AUTOSAR XML (schema 4-3-0)
package /E3_1_2_Premium
  system System
    system mapping Mapping_TestSwc_RGS_VL
      sw-mappings:
        swc to ecu mapping SwcMapping_TestSwc_RGS_VL: component=Geltungsbereich_E3_1_2_Premium.TestSwc, ecu-instance=RGS_VL
package /ComponentTypes
  composition sw component type Geltungsbereich_E3_1_2_Premium
    component TestSwc: type=TestSwc_RGS_VL
    delegate TestSwc.P_KN_RGS_VL_BusKnockOut <-> outer port P_KN_RGS_VL_BusKnockOut
    delegate TestSwc.P_KN_RGS_VL_BusKnockOutTimer <-> outer port P_KN_RGS_VL_BusKnockOutTimer
    delegate TestSwc.P_KN_RGS_VL_ECUKnockOut <-> outer port P_KN_RGS_VL_ECUKnockOut
    delegate TestSwc.P_KN_RGS_VL_ECUKnockOutTimer <-> outer port P_KN_RGS_VL_ECUKnockOutTimer
    delegate TestSwc.P_NM_RGS_VL_CBV_AWB <-> outer port P_NM_RGS_VL_CBV_AWB
    delegate TestSwc.P_NM_RGS_VL_CBV_CRI <-> outer port P_NM_RGS_VL_CBV_CRI
    delegate TestSwc.P_NM_RGS_VL_FCAB <-> outer port P_NM_RGS_VL_FCAB
    delegate TestSwc.P_NM_RGS_VL_FCIB <-> outer port P_NM_RGS_VL_FCIB
    delegate TestSwc.P_NM_RGS_VL_NM_State <-> outer port P_NM_RGS_VL_NM_State
    delegate TestSwc.P_NM_RGS_VL_NM_aktiv_Diag <-> outer port P_NM_RGS_VL_NM_aktiv_Diag
    delegate TestSwc.P_NM_RGS_VL_NM_aktiv_KL15 <-> outer port P_NM_RGS_VL_NM_aktiv_KL15
    delegate TestSwc.P_NM_RGS_VL_NM_aktiv_Mot_aktiv <-> outer port P_NM_RGS_VL_NM_aktiv_Mot_aktiv
    delegate TestSwc.P_NM_RGS_VL_NM_aktiv_Tmin <-> outer port P_NM_RGS_VL_NM_aktiv_Tmin
    delegate TestSwc.P_NM_RGS_VL_SNI_10 <-> outer port P_NM_RGS_VL_SNI_10
    delegate TestSwc.P_NM_RGS_VL_UDS_CC <-> outer port P_NM_RGS_VL_UDS_CC
    delegate TestSwc.P_NM_RGS_VL_Wakeup <-> outer port P_NM_RGS_VL_Wakeup
    delegate TestSwc.P_RGS_VL_Abschaltstufe <-> outer port P_RGS_VL_Abschaltstufe
    delegate TestSwc.P_RGS_VL_Bauteilfehler <-> outer port P_RGS_VL_Bauteilfehler
    delegate TestSwc.P_RGS_VL_Crashabschaltung <-> outer port P_RGS_VL_Crashabschaltung
    delegate TestSwc.P_RGS_VL_EEPROM_Datensatzfehler <-> outer port P_RGS_VL_EEPROM_Datensatzfehler
    delegate TestSwc.P_RGS_VL_Gurtbandauszug <-> outer port P_RGS_VL_Gurtbandauszug
    delegate TestSwc.P_RGS_VL_Gurtgeschwindigkeit <-> outer port P_RGS_VL_Gurtgeschwindigkeit
    delegate TestSwc.P_RGS_VL_InPos <-> outer port P_RGS_VL_InPos
    delegate TestSwc.P_RGS_VL_KD_Fehler <-> outer port P_RGS_VL_KD_Fehler
    delegate TestSwc.P_RGS_VL_Kommunikationsfehler_ASG <-> outer port P_RGS_VL_Kommunikationsfehler_ASG
    delegate TestSwc.P_RGS_VL_KompSchutz <-> outer port P_RGS_VL_KompSchutz
    delegate TestSwc.P_RGS_VL_Lokalaktiv <-> outer port P_RGS_VL_Lokalaktiv
    delegate TestSwc.P_RGS_VL_Max_Gurtlosezyklen <-> outer port P_RGS_VL_Max_Gurtlosezyklen
    delegate TestSwc.P_RGS_VL_Max_Haptikzyklenfehler <-> outer port P_RGS_VL_Max_Haptikzyklenfehler
    delegate TestSwc.P_RGS_VL_Max_Straffzyklenfehler <-> outer port P_RGS_VL_Max_Straffzyklenfehler
    delegate TestSwc.P_RGS_VL_Motorfehler <-> outer port P_RGS_VL_Motorfehler
    delegate TestSwc.P_RGS_VL_Nachlauftyp <-> outer port P_RGS_VL_Nachlauftyp
    delegate TestSwc.P_RGS_VL_SNI_10 <-> outer port P_RGS_VL_SNI_10
    delegate TestSwc.P_RGS_VL_Status <-> outer port P_RGS_VL_Status
    delegate TestSwc.P_RGS_VL_Strom <-> outer port P_RGS_VL_Strom
    delegate TestSwc.P_RGS_VL_Subsystemaktiv <-> outer port P_RGS_VL_Subsystemaktiv
    delegate TestSwc.P_RGS_VL_Temp <-> outer port P_RGS_VL_Temp
    delegate TestSwc.P_RGS_VL_Transport_Mode <-> outer port P_RGS_VL_Transport_Mode
    delegate TestSwc.P_RGS_VL_Ueberspannung <-> outer port P_RGS_VL_Ueberspannung
    delegate TestSwc.P_RGS_VL_Uebertemperatur_defekt <-> outer port P_RGS_VL_Uebertemperatur_defekt
    delegate TestSwc.P_RGS_VL_Unterspannung <-> outer port P_RGS_VL_Unterspannung
    delegate TestSwc.P_RGS_VL_keineStraffungUeberspg <-> outer port P_RGS_VL_keineStraffungUeberspg
    delegate TestSwc.P_RGS_VL_keineStraffungUnterspg <-> outer port P_RGS_VL_keineStraffungUnterspg
    delegate TestSwc.P_RGS_VL_nicht_programmiert <-> outer port P_RGS_VL_nicht_programmiert
    delegate TestSwc.R_NM_Airbag_01_FCAB <-> outer port R_NM_Airbag_01_FCAB
    delegate TestSwc.R_RGS_Nachlauf_allg <-> outer port R_RGS_Nachlauf_allg
    delegate TestSwc.R_RGS_VL_Anforderung <-> outer port R_RGS_VL_Anforderung
    delegate TestSwc.R_RGS_VL_Nachlauf_2 <-> outer port R_RGS_VL_Nachlauf_2
package /TestSwc_RGS_VL/SwComponentTypes
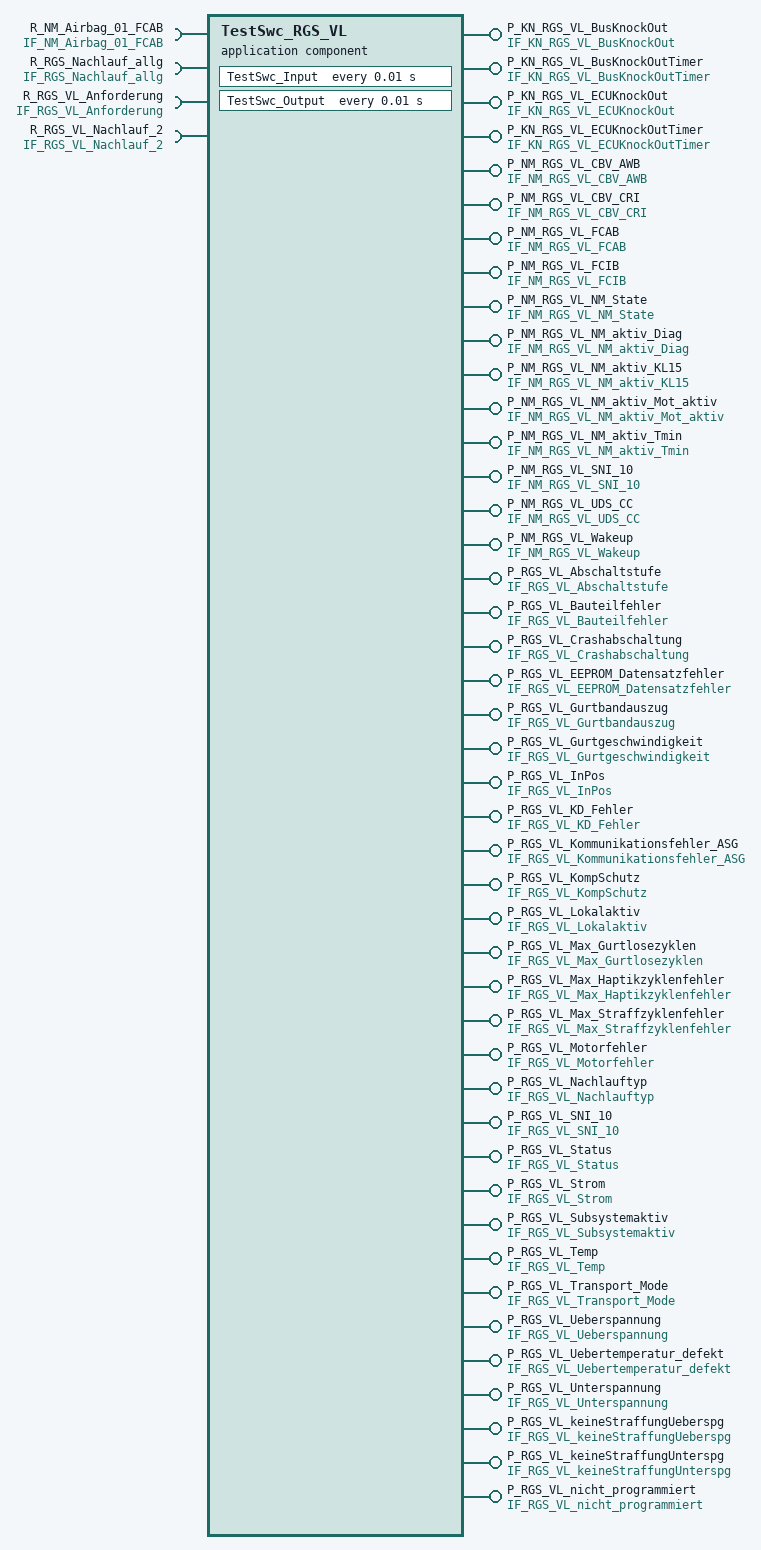
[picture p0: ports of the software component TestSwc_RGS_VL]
  application sw component type TestSwc_RGS_VL
    44 x provide port:
      P_KN_RGS_VL_BusKnockOut: nonqueued-sender-com-spec{data-element=KN_RGS_VL_BusKnockOut, handle-out-of-range=DEFAULT, init-value=constant-reference=Init_KN_RGS_VL_BusKnockOut}, provided-interface=IF_KN_RGS_VL_BusKnockOut
      P_KN_RGS_VL_BusKnockOutTimer: nonqueued-sender-com-spec{data-element=KN_RGS_VL_BusKnockOutTimer, handle-out-of-range=DEFAULT, init-value=constant-reference=Init_KN_RGS_VL_BusKnockOutTimer}, provided-interface=IF_KN_RGS_VL_BusKnockOutTimer
      P_KN_RGS_VL_ECUKnockOut: nonqueued-sender-com-spec{data-element=KN_RGS_VL_ECUKnockOut, handle-out-of-range=DEFAULT, init-value=constant-reference=Init_KN_RGS_VL_ECUKnockOut}, provided-interface=IF_KN_RGS_VL_ECUKnockOut
      P_KN_RGS_VL_ECUKnockOutTimer: nonqueued-sender-com-spec{data-element=KN_RGS_VL_ECUKnockOutTimer, handle-out-of-range=DEFAULT, init-value=constant-reference=Init_KN_RGS_VL_ECUKnockOutTimer}, provided-interface=IF_KN_RGS_VL_ECUKnockOutTimer
      P_NM_RGS_VL_CBV_AWB: nonqueued-sender-com-spec{data-element=NM_RGS_VL_CBV_AWB, handle-out-of-range=DEFAULT, init-value=constant-reference=Init_NM_RGS_VL_CBV_AWB}, provided-interface=IF_NM_RGS_VL_CBV_AWB
      P_NM_RGS_VL_CBV_CRI: nonqueued-sender-com-spec{data-element=NM_RGS_VL_CBV_CRI, handle-out-of-range=DEFAULT, init-value=constant-reference=Init_NM_RGS_VL_CBV_CRI}, provided-interface=IF_NM_RGS_VL_CBV_CRI
      P_NM_RGS_VL_FCAB: nonqueued-sender-com-spec{data-element=NM_RGS_VL_FCAB, handle-out-of-range=DEFAULT, init-value=constant-reference=Init_NM_RGS_VL_FCAB}, provided-interface=IF_NM_RGS_VL_FCAB
      P_NM_RGS_VL_FCIB: nonqueued-sender-com-spec{data-element=NM_RGS_VL_FCIB, handle-out-of-range=DEFAULT, init-value=constant-reference=Init_NM_RGS_VL_FCIB}, provided-interface=IF_NM_RGS_VL_FCIB
      P_NM_RGS_VL_NM_State: nonqueued-sender-com-spec{data-element=NM_RGS_VL_NM_State, handle-out-of-range=DEFAULT, init-value=constant-reference=Init_NM_RGS_VL_NM_State}, provided-interface=IF_NM_RGS_VL_NM_State
      P_NM_RGS_VL_NM_aktiv_Diag: nonqueued-sender-com-spec{data-element=NM_RGS_VL_NM_aktiv_Diag, handle-out-of-range=DEFAULT, init-value=constant-reference=Init_NM_RGS_VL_NM_aktiv_Diag}, provided-interface=IF_NM_RGS_VL_NM_aktiv_Diag
      P_NM_RGS_VL_NM_aktiv_KL15: nonqueued-sender-com-spec{data-element=NM_RGS_VL_NM_aktiv_KL15, handle-out-of-range=DEFAULT, init-value=constant-reference=Init_NM_RGS_VL_NM_aktiv_KL15}, provided-interface=IF_NM_RGS_VL_NM_aktiv_KL15
      P_NM_RGS_VL_NM_aktiv_Mot_aktiv: nonqueued-sender-com-spec{data-element=NM_RGS_VL_NM_aktiv_Mot_aktiv, handle-out-of-range=DEFAULT, init-value=constant-reference=Init_NM_RGS_VL_NM_aktiv_Mot_aktiv}, provided-interface=IF_NM_RGS_VL_NM_aktiv_Mot_aktiv
      P_NM_RGS_VL_NM_aktiv_Tmin: nonqueued-sender-com-spec{data-element=NM_RGS_VL_NM_aktiv_Tmin, handle-out-of-range=DEFAULT, init-value=constant-reference=Init_NM_RGS_VL_NM_aktiv_Tmin}, provided-interface=IF_NM_RGS_VL_NM_aktiv_Tmin
      P_NM_RGS_VL_SNI_10: nonqueued-sender-com-spec{data-element=NM_RGS_VL_SNI_10, handle-out-of-range=DEFAULT, init-value=constant-reference=Init_NM_RGS_VL_SNI_10}, provided-interface=IF_NM_RGS_VL_SNI_10
      P_NM_RGS_VL_UDS_CC: nonqueued-sender-com-spec{data-element=NM_RGS_VL_UDS_CC, handle-out-of-range=DEFAULT, init-value=constant-reference=Init_NM_RGS_VL_UDS_CC}, provided-interface=IF_NM_RGS_VL_UDS_CC
      P_NM_RGS_VL_Wakeup: nonqueued-sender-com-spec{data-element=NM_RGS_VL_Wakeup, handle-out-of-range=DEFAULT, init-value=constant-reference=Init_NM_RGS_VL_Wakeup}, provided-interface=IF_NM_RGS_VL_Wakeup
      P_RGS_VL_Abschaltstufe: nonqueued-sender-com-spec{data-element=RGS_VL_Abschaltstufe, handle-out-of-range=DEFAULT, init-value=constant-reference=Init_RGS_VL_Abschaltstufe}, provided-interface=IF_RGS_VL_Abschaltstufe
      P_RGS_VL_Bauteilfehler: nonqueued-sender-com-spec{data-element=RGS_VL_Bauteilfehler, handle-out-of-range=DEFAULT, init-value=constant-reference=Init_RGS_VL_Bauteilfehler}, provided-interface=IF_RGS_VL_Bauteilfehler
      P_RGS_VL_Crashabschaltung: nonqueued-sender-com-spec{data-element=RGS_VL_Crashabschaltung, handle-out-of-range=DEFAULT, init-value=constant-reference=Init_RGS_VL_Crashabschaltung}, provided-interface=IF_RGS_VL_Crashabschaltung
      P_RGS_VL_EEPROM_Datensatzfehler: nonqueued-sender-com-spec{data-element=RGS_VL_EEPROM_Datensatzfehler, handle-out-of-range=DEFAULT, init-value=constant-reference=Init_RGS_VL_EEPROM_Datensatzfehler}, provided-interface=IF_RGS_VL_EEPROM_Datensatzfehler
      P_RGS_VL_Gurtbandauszug: nonqueued-sender-com-spec{data-element=RGS_VL_Gurtbandauszug, handle-out-of-range=DEFAULT, init-value=constant-reference=Init_RGS_VL_Gurtbandauszug}, provided-interface=IF_RGS_VL_Gurtbandauszug
      P_RGS_VL_Gurtgeschwindigkeit: nonqueued-sender-com-spec{data-element=RGS_VL_Gurtgeschwindigkeit, handle-out-of-range=DEFAULT, init-value=constant-reference=Init_RGS_VL_Gurtgeschwindigkeit}, provided-interface=IF_RGS_VL_Gurtgeschwindigkeit
      P_RGS_VL_InPos: nonqueued-sender-com-spec{data-element=RGS_VL_InPos, handle-out-of-range=DEFAULT, init-value=constant-reference=Init_RGS_VL_InPos}, provided-interface=IF_RGS_VL_InPos
      P_RGS_VL_KD_Fehler: nonqueued-sender-com-spec{data-element=RGS_VL_KD_Fehler, handle-out-of-range=DEFAULT, init-value=constant-reference=Init_RGS_VL_KD_Fehler}, provided-interface=IF_RGS_VL_KD_Fehler
      P_RGS_VL_Kommunikationsfehler_ASG: nonqueued-sender-com-spec{data-element=RGS_VL_Kommunikationsfehler_ASG, handle-out-of-range=DEFAULT, init-value=constant-reference=Init_RGS_VL_Kommunikationsfehler_ASG}, provided-interface=IF_RGS_VL_Kommunikationsfehler_ASG
      P_RGS_VL_KompSchutz: nonqueued-sender-com-spec{data-element=RGS_VL_KompSchutz, handle-out-of-range=DEFAULT, init-value=constant-reference=Init_RGS_VL_KompSchutz}, provided-interface=IF_RGS_VL_KompSchutz
      P_RGS_VL_Lokalaktiv: nonqueued-sender-com-spec{data-element=RGS_VL_Lokalaktiv, handle-out-of-range=DEFAULT, init-value=constant-reference=Init_RGS_VL_Lokalaktiv}, provided-interface=IF_RGS_VL_Lokalaktiv
      P_RGS_VL_Max_Gurtlosezyklen: nonqueued-sender-com-spec{data-element=RGS_VL_Max_Gurtlosezyklen, handle-out-of-range=DEFAULT, init-value=constant-reference=Init_RGS_VL_Max_Gurtlosezyklen}, provided-interface=IF_RGS_VL_Max_Gurtlosezyklen
      P_RGS_VL_Max_Haptikzyklenfehler: nonqueued-sender-com-spec{data-element=RGS_VL_Max_Haptikzyklenfehler, handle-out-of-range=DEFAULT, init-value=constant-reference=Init_RGS_VL_Max_Haptikzyklenfehler}, provided-interface=IF_RGS_VL_Max_Haptikzyklenfehler
      P_RGS_VL_Max_Straffzyklenfehler: nonqueued-sender-com-spec{data-element=RGS_VL_Max_Straffzyklenfehler, handle-out-of-range=DEFAULT, init-value=constant-reference=Init_RGS_VL_Max_Straffzyklenfehler}, provided-interface=IF_RGS_VL_Max_Straffzyklenfehler
      P_RGS_VL_Motorfehler: nonqueued-sender-com-spec{data-element=RGS_VL_Motorfehler, handle-out-of-range=DEFAULT, init-value=constant-reference=Init_RGS_VL_Motorfehler}, provided-interface=IF_RGS_VL_Motorfehler
      P_RGS_VL_Nachlauftyp: nonqueued-sender-com-spec{data-element=RGS_VL_Nachlauftyp, handle-out-of-range=DEFAULT, init-value=constant-reference=Init_RGS_VL_Nachlauftyp}, provided-interface=IF_RGS_VL_Nachlauftyp
      P_RGS_VL_SNI_10: nonqueued-sender-com-spec{data-element=RGS_VL_SNI_10, handle-out-of-range=DEFAULT, init-value=constant-reference=Init_RGS_VL_SNI_10}, provided-interface=IF_RGS_VL_SNI_10
      P_RGS_VL_Status: nonqueued-sender-com-spec{data-element=RGS_VL_Status, handle-out-of-range=DEFAULT, init-value=constant-reference=Init_RGS_VL_Status}, provided-interface=IF_RGS_VL_Status
      P_RGS_VL_Strom: nonqueued-sender-com-spec{data-element=RGS_VL_Strom, handle-out-of-range=DEFAULT, init-value=constant-reference=Init_RGS_VL_Strom}, provided-interface=IF_RGS_VL_Strom
      P_RGS_VL_Subsystemaktiv: nonqueued-sender-com-spec{data-element=RGS_VL_Subsystemaktiv, handle-out-of-range=DEFAULT, init-value=constant-reference=Init_RGS_VL_Subsystemaktiv}, provided-interface=IF_RGS_VL_Subsystemaktiv
      P_RGS_VL_Temp: nonqueued-sender-com-spec{data-element=RGS_VL_Temp, handle-out-of-range=DEFAULT, init-value=constant-reference=Init_RGS_VL_Temp}, provided-interface=IF_RGS_VL_Temp
      P_RGS_VL_Transport_Mode: nonqueued-sender-com-spec{data-element=RGS_VL_Transport_Mode, handle-out-of-range=DEFAULT, init-value=constant-reference=Init_RGS_VL_Transport_Mode}, provided-interface=IF_RGS_VL_Transport_Mode
      P_RGS_VL_Ueberspannung: nonqueued-sender-com-spec{data-element=RGS_VL_Ueberspannung, handle-out-of-range=DEFAULT, init-value=constant-reference=Init_RGS_VL_Ueberspannung}, provided-interface=IF_RGS_VL_Ueberspannung
      P_RGS_VL_Uebertemperatur_defekt: nonqueued-sender-com-spec{data-element=RGS_VL_Uebertemperatur_defekt, handle-out-of-range=DEFAULT, init-value=constant-reference=Init_RGS_VL_Uebertemperatur_defekt}, provided-interface=IF_RGS_VL_Uebertemperatur_defekt
      P_RGS_VL_Unterspannung: nonqueued-sender-com-spec{data-element=RGS_VL_Unterspannung, handle-out-of-range=DEFAULT, init-value=constant-reference=Init_RGS_VL_Unterspannung}, provided-interface=IF_RGS_VL_Unterspannung
      P_RGS_VL_keineStraffungUeberspg: nonqueued-sender-com-spec{data-element=RGS_VL_keineStraffungUeberspg, handle-out-of-range=DEFAULT, init-value=constant-reference=Init_RGS_VL_keineStraffungUeberspg}, provided-interface=IF_RGS_VL_keineStraffungUeberspg
      P_RGS_VL_keineStraffungUnterspg: nonqueued-sender-com-spec{data-element=RGS_VL_keineStraffungUnterspg, handle-out-of-range=DEFAULT, init-value=constant-reference=Init_RGS_VL_keineStraffungUnterspg}, provided-interface=IF_RGS_VL_keineStraffungUnterspg
      P_RGS_VL_nicht_programmiert: nonqueued-sender-com-spec{data-element=RGS_VL_nicht_programmiert, handle-out-of-range=DEFAULT, init-value=constant-reference=Init_RGS_VL_nicht_programmiert}, provided-interface=IF_RGS_VL_nicht_programmiert
    4 x require port:
      R_NM_Airbag_01_FCAB: nonqueued-receiver-com-spec{data-element=NM_Airbag_01_FCAB, handle-out-of-range=DEFAULT, alive-timeout=2.0, enable-update=true, init-value=constant-reference=Init_NM_Airbag_01_FCAB}, required-interface=IF_NM_Airbag_01_FCAB
      R_RGS_Nachlauf_allg: nonqueued-receiver-com-spec{data-element=RGS_Nachlauf_allg, handle-out-of-range=DEFAULT, alive-timeout=5.0, enable-update=true, init-value=constant-reference=Init_RGS_Nachlauf_allg}, required-interface=IF_RGS_Nachlauf_allg
      R_RGS_VL_Anforderung: nonqueued-receiver-com-spec{data-element=RGS_VL_Anforderung, handle-out-of-range=DEFAULT, alive-timeout=5.0, enable-update=true, init-value=constant-reference=Init_RGS_VL_Anforderung}, required-interface=IF_RGS_VL_Anforderung
      R_RGS_VL_Nachlauf_2: nonqueued-receiver-com-spec{data-element=RGS_VL_Nachlauf_2, handle-out-of-range=DEFAULT, alive-timeout=5.0, enable-update=true, init-value=constant-reference=Init_RGS_VL_Nachlauf_2}, required-interface=IF_RGS_VL_Nachlauf_2
    behavior SwcIb: handle-termination-and-restart=NO-SUPPORT
      timing event EventTestSwc_Input: start-on-event=TestSwc_Input, period=0.01
      timing event EventTestSwc_Output: start-on-event=TestSwc_Output, period=0.01
      runnable TestSwc_Input
        data-receive-point-by-arguments:
          4 x access:
            VA_NM_Airbag_01_FCAB: accessed-variable=R_NM_Airbag_01_FCAB.NM_Airbag_01_FCAB
            VA_RGS_Nachlauf_allg: accessed-variable=R_RGS_Nachlauf_allg.RGS_Nachlauf_allg
            VA_RGS_VL_Anforderung: accessed-variable=R_RGS_VL_Anforderung.RGS_VL_Anforderung
            VA_RGS_VL_Nachlauf_2: accessed-variable=R_RGS_VL_Nachlauf_2.RGS_VL_Nachlauf_2
      runnable TestSwc_Output
        data-send-points:
          44 x access:
            VA_KN_RGS_VL_BusKnockOut: accessed-variable=P_KN_RGS_VL_BusKnockOut.KN_RGS_VL_BusKnockOut
            VA_KN_RGS_VL_BusKnockOutTimer: accessed-variable=P_KN_RGS_VL_BusKnockOutTimer.KN_RGS_VL_BusKnockOutTimer
            VA_KN_RGS_VL_ECUKnockOut: accessed-variable=P_KN_RGS_VL_ECUKnockOut.KN_RGS_VL_ECUKnockOut
            VA_KN_RGS_VL_ECUKnockOutTimer: accessed-variable=P_KN_RGS_VL_ECUKnockOutTimer.KN_RGS_VL_ECUKnockOutTimer
            VA_NM_RGS_VL_CBV_AWB: accessed-variable=P_NM_RGS_VL_CBV_AWB.NM_RGS_VL_CBV_AWB
            VA_NM_RGS_VL_CBV_CRI: accessed-variable=P_NM_RGS_VL_CBV_CRI.NM_RGS_VL_CBV_CRI
            VA_NM_RGS_VL_FCAB: accessed-variable=P_NM_RGS_VL_FCAB.NM_RGS_VL_FCAB
            VA_NM_RGS_VL_FCIB: accessed-variable=P_NM_RGS_VL_FCIB.NM_RGS_VL_FCIB
            VA_NM_RGS_VL_NM_State: accessed-variable=P_NM_RGS_VL_NM_State.NM_RGS_VL_NM_State
            VA_NM_RGS_VL_NM_aktiv_Diag: accessed-variable=P_NM_RGS_VL_NM_aktiv_Diag.NM_RGS_VL_NM_aktiv_Diag
            VA_NM_RGS_VL_NM_aktiv_KL15: accessed-variable=P_NM_RGS_VL_NM_aktiv_KL15.NM_RGS_VL_NM_aktiv_KL15
            VA_NM_RGS_VL_NM_aktiv_Mot_aktiv: accessed-variable=P_NM_RGS_VL_NM_aktiv_Mot_aktiv.NM_RGS_VL_NM_aktiv_Mot_aktiv
            VA_NM_RGS_VL_NM_aktiv_Tmin: accessed-variable=P_NM_RGS_VL_NM_aktiv_Tmin.NM_RGS_VL_NM_aktiv_Tmin
            VA_NM_RGS_VL_SNI_10: accessed-variable=P_NM_RGS_VL_SNI_10.NM_RGS_VL_SNI_10
            VA_NM_RGS_VL_UDS_CC: accessed-variable=P_NM_RGS_VL_UDS_CC.NM_RGS_VL_UDS_CC
            VA_NM_RGS_VL_Wakeup: accessed-variable=P_NM_RGS_VL_Wakeup.NM_RGS_VL_Wakeup
            VA_RGS_VL_Abschaltstufe: accessed-variable=P_RGS_VL_Abschaltstufe.RGS_VL_Abschaltstufe
            VA_RGS_VL_Bauteilfehler: accessed-variable=P_RGS_VL_Bauteilfehler.RGS_VL_Bauteilfehler
            VA_RGS_VL_Crashabschaltung: accessed-variable=P_RGS_VL_Crashabschaltung.RGS_VL_Crashabschaltung
            VA_RGS_VL_EEPROM_Datensatzfehler: accessed-variable=P_RGS_VL_EEPROM_Datensatzfehler.RGS_VL_EEPROM_Datensatzfehler
            VA_RGS_VL_Gurtbandauszug: accessed-variable=P_RGS_VL_Gurtbandauszug.RGS_VL_Gurtbandauszug
            VA_RGS_VL_Gurtgeschwindigkeit: accessed-variable=P_RGS_VL_Gurtgeschwindigkeit.RGS_VL_Gurtgeschwindigkeit
            VA_RGS_VL_InPos: accessed-variable=P_RGS_VL_InPos.RGS_VL_InPos
            VA_RGS_VL_KD_Fehler: accessed-variable=P_RGS_VL_KD_Fehler.RGS_VL_KD_Fehler
            VA_RGS_VL_Kommunikationsfehler_ASG: accessed-variable=P_RGS_VL_Kommunikationsfehler_ASG.RGS_VL_Kommunikationsfehler_ASG
            VA_RGS_VL_KompSchutz: accessed-variable=P_RGS_VL_KompSchutz.RGS_VL_KompSchutz
            VA_RGS_VL_Lokalaktiv: accessed-variable=P_RGS_VL_Lokalaktiv.RGS_VL_Lokalaktiv
            VA_RGS_VL_Max_Gurtlosezyklen: accessed-variable=P_RGS_VL_Max_Gurtlosezyklen.RGS_VL_Max_Gurtlosezyklen
            VA_RGS_VL_Max_Haptikzyklenfehler: accessed-variable=P_RGS_VL_Max_Haptikzyklenfehler.RGS_VL_Max_Haptikzyklenfehler
            VA_RGS_VL_Max_Straffzyklenfehler: accessed-variable=P_RGS_VL_Max_Straffzyklenfehler.RGS_VL_Max_Straffzyklenfehler
            VA_RGS_VL_Motorfehler: accessed-variable=P_RGS_VL_Motorfehler.RGS_VL_Motorfehler
            VA_RGS_VL_Nachlauftyp: accessed-variable=P_RGS_VL_Nachlauftyp.RGS_VL_Nachlauftyp
            VA_RGS_VL_SNI_10: accessed-variable=P_RGS_VL_SNI_10.RGS_VL_SNI_10
            VA_RGS_VL_Status: accessed-variable=P_RGS_VL_Status.RGS_VL_Status
            VA_RGS_VL_Strom: accessed-variable=P_RGS_VL_Strom.RGS_VL_Strom
            VA_RGS_VL_Subsystemaktiv: accessed-variable=P_RGS_VL_Subsystemaktiv.RGS_VL_Subsystemaktiv
            VA_RGS_VL_Temp: accessed-variable=P_RGS_VL_Temp.RGS_VL_Temp
            VA_RGS_VL_Transport_Mode: accessed-variable=P_RGS_VL_Transport_Mode.RGS_VL_Transport_Mode
            VA_RGS_VL_Ueberspannung: accessed-variable=P_RGS_VL_Ueberspannung.RGS_VL_Ueberspannung
            VA_RGS_VL_Uebertemperatur_defekt: accessed-variable=P_RGS_VL_Uebertemperatur_defekt.RGS_VL_Uebertemperatur_defekt
            VA_RGS_VL_Unterspannung: accessed-variable=P_RGS_VL_Unterspannung.RGS_VL_Unterspannung
            VA_RGS_VL_keineStraffungUeberspg: accessed-variable=P_RGS_VL_keineStraffungUeberspg.RGS_VL_keineStraffungUeberspg
            VA_RGS_VL_keineStraffungUnterspg: accessed-variable=P_RGS_VL_keineStraffungUnterspg.RGS_VL_keineStraffungUnterspg
            VA_RGS_VL_nicht_programmiert: accessed-variable=P_RGS_VL_nicht_programmiert.RGS_VL_nicht_programmiert
package /TestSwc_RGS_VL/SwcImplementations
  swc implementation Imp_TestSwc_RGS_VL: programming-language=C, sw-version=1.0.0, vendor-id=1, behavior=SwcIb
    code-descriptors:
      code SRC: artifact-descriptors=autosar-engineering-object={short-label=EngObj, category=SWCSRC}
    resource consumption ResourceConsumption
      memory section CODE: sw-addrmethod=CODE
